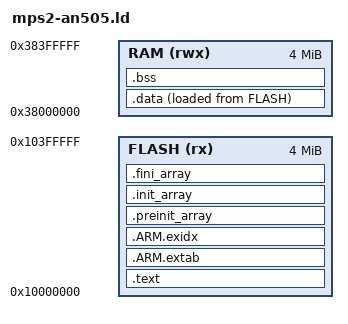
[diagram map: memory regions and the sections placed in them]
/* QEMU mps2-an505 (Cortex-M33, starts in Secure state): code in SSRAM1 through its secure alias, data in
 * SSRAM2/3 through theirs. Code linked at the non-secure alias 0 locks up on the first fetch (HardFault
 * escalation); RAM at 0x38000000 is the secure alias of 0x28000000. */
MEMORY
{
  FLASH (rx) : ORIGIN = 0x10000000, LENGTH = 4M
  RAM (rwx)  : ORIGIN = 0x38000000, LENGTH = 4M
}

ENTRY(Reset_Handler)

SECTIONS
{
  .text :
  {
    KEEP(*(.isr_vector))
    *(.text*)
    *(.rodata*)
    KEEP(*(.init))
    KEEP(*(.fini))
    . = ALIGN(4);
  } > FLASH

  .ARM.extab : { *(.ARM.extab* .gnu.linkonce.armextab.*) } > FLASH
  .ARM.exidx :
  {
    __exidx_start = .;
    *(.ARM.exidx* .gnu.linkonce.armexidx.*)
    __exidx_end = .;
  } > FLASH

  .preinit_array :
  {
    PROVIDE_HIDDEN(__preinit_array_start = .);
    KEEP(*(.preinit_array*))
    PROVIDE_HIDDEN(__preinit_array_end = .);
  } > FLASH
  .init_array :
  {
    PROVIDE_HIDDEN(__init_array_start = .);
    KEEP(*(SORT(.init_array.*)))
    KEEP(*(.init_array*))
    PROVIDE_HIDDEN(__init_array_end = .);
  } > FLASH
  .fini_array :
  {
    PROVIDE_HIDDEN(__fini_array_start = .);
    KEEP(*(SORT(.fini_array.*)))
    KEEP(*(.fini_array*))
    PROVIDE_HIDDEN(__fini_array_end = .);
  } > FLASH

  _sidata = LOADADDR(.data);
  .data :
  {
    . = ALIGN(4);
    _sdata = .;
    *(.data*)
    . = ALIGN(4);
    _edata = .;
  } > RAM AT > FLASH

  .bss (NOLOAD) :
  {
    . = ALIGN(4);
    _sbss = .;
    __bss_start__ = .;
    *(.bss*)
    *(COMMON)
    . = ALIGN(4);
    _ebss = .;
    __bss_end__ = .;
  } > RAM

  . = ALIGN(8);
  end = .;
  _end = .;
  __end__ = .;
  __stack_top = ORIGIN(RAM) + LENGTH(RAM);
  __stack = __stack_top;
}
